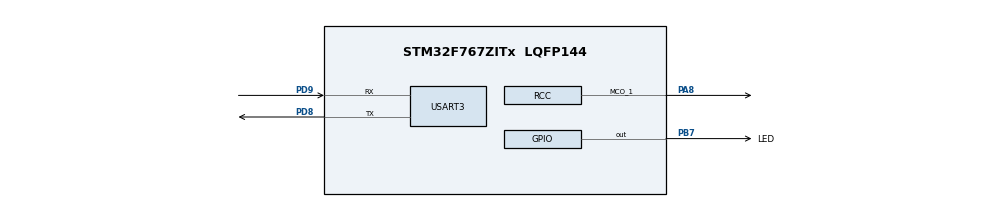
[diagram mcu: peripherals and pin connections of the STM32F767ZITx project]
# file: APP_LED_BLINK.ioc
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CORTEX_M7.default_mode_Activation=1
FREERTOS.Tasks01=defaultTask,24,256,StartDefaultTask,Default,NULL,Dynamic,NULL,NULL;LED_Task_10ms,24,256,StartTask02,Default,NULL,Dynamic,NULL,NULL
Mcu.Family=STM32F7
Mcu.Name=STM32F767ZITx
Mcu.Package=LQFP144
NVIC.PriorityGroup=NVIC_PRIORITYGROUP_4
NVIC.TIM6_DAC_IRQn=true\:15\:0\:false\:false\:true\:false\:false\:true\:true
NVIC.TimeBase=TIM6_DAC_IRQn
NVIC.TimeBaseIP=TIM6
NVIC.USART3_IRQn=true\:5\:0\:false\:false\:true\:true\:true\:true\:true
PA8.Mode=Clock-out-1
PA8.Signal=RCC_MCO_1
PB7.GPIO_Label=LED
PB7.Signal=GPIO_Output
PD8.Mode=Asynchronous
PD8.Signal=USART3_TX
PD9.Mode=Asynchronous
PD9.Signal=USART3_RX
PH0/OSC_IN.Mode=HSE-External-Oscillator
PH0/OSC_IN.Signal=RCC_OSC_IN
PH1/OSC_OUT.Mode=HSE-External-Oscillator
PH1/OSC_OUT.Signal=RCC_OSC_OUT
ProjectManager.HeapSize=0x200
ProjectManager.StackSize=0x400
ProjectManager.TargetToolchain=STM32CubeIDE
RCC.HSE_VALUE=25000000
RCC.HSI_VALUE=16000000
RCC.LSE_VALUE=32768
RCC.USBFreq_Value=96000000
RCC.VCOOutputFreq_Value=192000000
USART3.VirtualMode-Asynchronous=VM_ASYNC
VP_FREERTOS_VS_CMSIS_V2.Mode=CMSIS_V2
VP_SYS_VS_tim6.Mode=TIM6
board=custom

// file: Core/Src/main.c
/* USER CODE BEGIN Header */
/**
  ******************************************************************************
  * @file           : main.c
  * @brief          : Main program body
  ******************************************************************************
  * @attention
  *
  * Copyright (c) 2026 STMicroelectronics.
  * All rights reserved.
  *
  * This software is licensed under terms that can be found in the LICENSE file
  * in the root directory of this software component.
  * If no LICENSE file comes with this software, it is provided AS-IS.
  *
  ******************************************************************************
  */
/* USER CODE END Header */
#include "main.h"
#include "cmsis_os.h"
#include "APP_LED.h"
//#include "APP_LED.h"

UART_HandleTypeDef huart3;

/* Definitions for defaultTask */
osThreadId_t defaultTaskHandle;
const osThreadAttr_t defaultTask_attributes = {
  .name = "defaultTask",
  .stack_size = 256 * 4,
  .priority = (osPriority_t) osPriorityNormal,
};
/* Definitions for LED_Task_10ms */
osThreadId_t LED_Task_10msHandle;
const osThreadAttr_t LED_Task_10ms_attributes = {
  .name = "LED_Task_10ms",
  .stack_size = 256 * 4,
  .priority = (osPriority_t) osPriorityNormal,
};

void SystemClock_Config(void);
static void MPU_Config(void);
static void MX_GPIO_Init(void);
static void MX_USART3_UART_Init(void);
void StartDefaultTask(void *argument);

int main(void)
{

  /* MPU Configuration--------------------------------------------------------*/
  MPU_Config();

  /* MCU Configuration--------------------------------------------------------*/

  /* Reset of all peripherals, Initializes the Flash interface and the Systick. */
  HAL_Init();

  /* Configure the system clock */
  SystemClock_Config();

  /* Initialize all configured peripherals */
  MX_GPIO_Init();
  MX_USART3_UART_Init();
  /* USER CODE BEGIN 2 */
  UART_Manager_Init();

  /* USER CODE END 2 */

  /* Init scheduler */
  osKernelInitialize();

  /* Create the thread(s) */
  /* creation of defaultTask */
  defaultTaskHandle = osThreadNew(StartDefaultTask, NULL, &defaultTask_attributes);

  /* creation of LED_Task_10ms */
  LED_Task_10msHandle = osThreadNew(StartTask02, NULL, &LED_Task_10ms_attributes);

  /* Start scheduler */
  osKernelStart();

  /* We should never get here as control is now taken by the scheduler */

  /* Infinite loop */
  /* USER CODE BEGIN WHILE */
  char MSG[] = "HELLO\r\n";
  while (1)
  {
	 // printf("%s\n",RX_Buffer);

	  	  	  //printf("%c",RX_Buffer);

	  //HAL_UART_Transmit(&huart3, (uint8_t*)MSG, strlen(MSG), 100);
	  //UART_Manager_5ms();

    /* USER CODE END WHILE */

  }
}

void SystemClock_Config(void)
{
  RCC_OscInitTypeDef RCC_OscInitStruct = {0};
  RCC_ClkInitTypeDef RCC_ClkInitStruct = {0};

  /** Configure the main internal regulator output voltage
  */
  __HAL_RCC_PWR_CLK_ENABLE();
  __HAL_PWR_VOLTAGESCALING_CONFIG(PWR_REGULATOR_VOLTAGE_SCALE3);

  /** Initializes the RCC Oscillators according to the specified parameters
  * in the RCC_OscInitTypeDef structure.
  */
  RCC_OscInitStruct.OscillatorType = RCC_OSCILLATORTYPE_HSI;
  RCC_OscInitStruct.HSIState = RCC_HSI_ON;
  RCC_OscInitStruct.HSICalibrationValue = RCC_HSICALIBRATION_DEFAULT;
  RCC_OscInitStruct.PLL.PLLState = RCC_PLL_NONE;
  if (HAL_RCC_OscConfig(&RCC_OscInitStruct) != HAL_OK)
  {
    Error_Handler();
  }

  /** Initializes the CPU, AHB and APB buses clocks
  */
  RCC_ClkInitStruct.ClockType = RCC_CLOCKTYPE_HCLK|RCC_CLOCKTYPE_SYSCLK
                              |RCC_CLOCKTYPE_PCLK1|RCC_CLOCKTYPE_PCLK2;
  RCC_ClkInitStruct.SYSCLKSource = RCC_SYSCLKSOURCE_HSI;
  RCC_ClkInitStruct.AHBCLKDivider = RCC_SYSCLK_DIV1;
  RCC_ClkInitStruct.APB1CLKDivider = RCC_HCLK_DIV1;
  RCC_ClkInitStruct.APB2CLKDivider = RCC_HCLK_DIV1;

  if (HAL_RCC_ClockConfig(&RCC_ClkInitStruct, FLASH_LATENCY_0) != HAL_OK)
  {
    Error_Handler();
  }
  HAL_RCC_MCOConfig(RCC_MCO1, RCC_MCO1SOURCE_HSI, RCC_MCODIV_1);
}

static void MX_USART3_UART_Init(void)
{

  huart3.Instance = USART3;
  huart3.Init.BaudRate = 115200;
  huart3.Init.WordLength = UART_WORDLENGTH_8B;
  huart3.Init.StopBits = UART_STOPBITS_1;
  huart3.Init.Parity = UART_PARITY_NONE;
  huart3.Init.Mode = UART_MODE_TX_RX;
  huart3.Init.HwFlowCtl = UART_HWCONTROL_NONE;
  huart3.Init.OverSampling = UART_OVERSAMPLING_16;
  huart3.Init.OneBitSampling = UART_ONE_BIT_SAMPLE_DISABLE;
  huart3.AdvancedInit.AdvFeatureInit = UART_ADVFEATURE_NO_INIT;
  if (HAL_UART_Init(&huart3) != HAL_OK)
  {
    Error_Handler();
  }

}

static void MX_GPIO_Init(void)
{
  GPIO_InitTypeDef GPIO_InitStruct = {0};

  /* GPIO Ports Clock Enable */
  __HAL_RCC_GPIOH_CLK_ENABLE();
  __HAL_RCC_GPIOD_CLK_ENABLE();
  __HAL_RCC_GPIOA_CLK_ENABLE();
  __HAL_RCC_GPIOB_CLK_ENABLE();

  /*Configure GPIO pin Output Level */
  HAL_GPIO_WritePin(LED_GPIO_Port, LED_Pin, GPIO_PIN_RESET);

  /*Configure GPIO pin : PA8 */
  GPIO_InitStruct.Pin = GPIO_PIN_8;
  GPIO_InitStruct.Mode = GPIO_MODE_AF_PP;
  GPIO_InitStruct.Pull = GPIO_NOPULL;
  GPIO_InitStruct.Speed = GPIO_SPEED_FREQ_LOW;
  GPIO_InitStruct.Alternate = GPIO_AF0_MCO;
  HAL_GPIO_Init(GPIOA, &GPIO_InitStruct);

  /*Configure GPIO pin : LED_Pin */
  GPIO_InitStruct.Pin = LED_Pin;
  GPIO_InitStruct.Mode = GPIO_MODE_OUTPUT_PP;
  GPIO_InitStruct.Pull = GPIO_NOPULL;
  GPIO_InitStruct.Speed = GPIO_SPEED_FREQ_LOW;
  HAL_GPIO_Init(LED_GPIO_Port, &GPIO_InitStruct);

}

void StartDefaultTask(void *argument)
{
  for(;;)
  {
    osDelay(1);
  }
}

 /* MPU Configuration */

void MPU_Config(void)
{
  MPU_Region_InitTypeDef MPU_InitStruct = {0};

  /* Disables the MPU */
  HAL_MPU_Disable();

  /** Initializes and configures the Region and the memory to be protected
  */
  MPU_InitStruct.Enable = MPU_REGION_ENABLE;
  MPU_InitStruct.Number = MPU_REGION_NUMBER0;
  MPU_InitStruct.BaseAddress = 0x0;
  MPU_InitStruct.Size = MPU_REGION_SIZE_4GB;
  MPU_InitStruct.SubRegionDisable = 0x87;
  MPU_InitStruct.TypeExtField = MPU_TEX_LEVEL0;
  MPU_InitStruct.AccessPermission = MPU_REGION_NO_ACCESS;
  MPU_InitStruct.DisableExec = MPU_INSTRUCTION_ACCESS_DISABLE;
  MPU_InitStruct.IsShareable = MPU_ACCESS_SHAREABLE;
  MPU_InitStruct.IsCacheable = MPU_ACCESS_NOT_CACHEABLE;
  MPU_InitStruct.IsBufferable = MPU_ACCESS_NOT_BUFFERABLE;

  HAL_MPU_ConfigRegion(&MPU_InitStruct);
  /* Enables the MPU */
  HAL_MPU_Enable(MPU_PRIVILEGED_DEFAULT);

}

void HAL_TIM_PeriodElapsedCallback(TIM_HandleTypeDef *htim)
{
  if (htim->Instance == TIM6)
  {
    HAL_IncTick();
  }
}

void Error_Handler(void)
{
  __disable_irq();
}
